# CY8C5667AXI_LP040 register map
File version: 0.1
CY8C56LP
Registers are 8-bit, read-write, no defined reset value unless marked. A register's access mark holds for its fields unless they carry their own. Offsets are from the block's base; lines under a group give offsets from that group; [hi:lo] are bit positions; {n}, {i} and the like mark numbered series; 'fields as' and 'values as' point back to an identical list; <NAME> marks a mode.

## Memory map
0x00000000 ResistiveTouch_1_ADC
0x00000000 UART_1 — UART
0x00000000 DESULFATE_PWMGEN
0x00000000 BACKLIGHT_PWMGEN
0x00000000 SPIS_1
0x00000000 I2C_1
0x00000000 RTC_1 — RTC
0x40006463 TMP05_1_TMP05_STS
0x4000646A FAN_STATUS_REG
0x40006479 PWM_ENABLE_REG
0x40006578 SENSOR_SELECT

## PWM_ENABLE_REG
Base 0x40006479
0x00 PWM_ENABLE_REG_CONTROL_REG

## SENSOR_SELECT
Base 0x40006578
Registers as PWM_ENABLE_REG (with PWM_ENABLE_REG read as SENSOR_SELECT).

## UART_1 — UART
Base 0x00000000
0x40006425 RX_UART_1_RX_ADDRESS1 — RX Address1 Register
0x40006435 RX_UART_1_RX_ADDRESS2 — RX Address2 Register
0x40006445 RX_UART_1_RX_DATA — RX Data Register
0x40006447 TX_UART_1_TX_DATA — TX Data Register
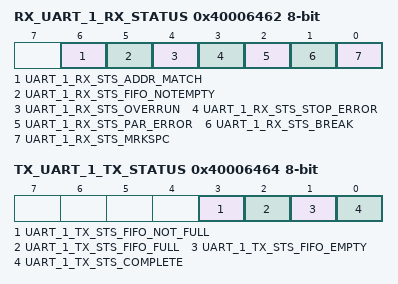
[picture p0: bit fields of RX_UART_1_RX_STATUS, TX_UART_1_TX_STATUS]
0x40006462 RX_UART_1_RX_STATUS — RX status register
  [6] UART_1_RX_STS_ADDR_MATCH ro, [5] UART_1_RX_STS_FIFO_NOTEMPTY ro, [4] UART_1_RX_STS_OVERRUN ro, [3] UART_1_RX_STS_STOP_ERROR ro, [2] UART_1_RX_STS_PAR_ERROR ro, [1] UART_1_RX_STS_BREAK ro, [0] UART_1_RX_STS_MRKSPC ro
0x40006464 TX_UART_1_TX_STATUS — TX status register
  [3] UART_1_TX_STS_FIFO_NOT_FULL ro, [2] UART_1_TX_STS_FIFO_FULL ro, [1] UART_1_TX_STS_FIFO_EMPTY ro, [0] UART_1_TX_STS_COMPLETE ro

## FAN_STATUS_REG
Base 0x4000646A
0x00 FAN_STATUS_REG_STATUS_REG
0x20 FAN_STATUS_REG_MASK_REG
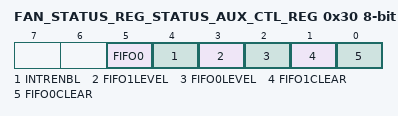
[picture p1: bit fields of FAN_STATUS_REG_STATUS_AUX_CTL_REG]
0x30 FAN_STATUS_REG_STATUS_AUX_CTL_REG
  [5] FIFO0 — FIFO0 clear
    1=ENABLED (Enable counter); 0=DISABLED (Disable counter)
  [4] INTRENBL — Enables or disables the Interrupt
    1=ENABLED (Interrupt enabled); 0=DISABLED (Interrupt disabled)
  [3] FIFO1LEVEL — FIFO level
    1=ENABLED (FIFO LVL: input mode: FIFO at least 1/2 empty; output mode: FIFO at least 1/2 full); 0=DISABLED (FIFO LVL: input mode: FIFO not full; output mode: FIFO not empty)
  [2] FIFO0LEVEL — FIFO level
    values as FIFO1LEVEL
  [1] FIFO1CLEAR — FIFO clear
    1=ENABLED (Clear FIFO state); 0=DISABLED (Normal FIFO operation)
  [0] FIFO0CLEAR — FIFO clear
    values as FIFO1CLEAR

## TMP05_1_TMP05_STS
Base 0x40006463
Registers as FAN_STATUS_REG (with FAN_STATUS_REG read as TMP05_1_TMP05_STS).

## DESULFATE_PWMGEN
Base 0x00000000
0x40006526 DESULFATE_PWMGEN_COMPARE_Reg_ — UDB.D0 - Assigned Compare Value
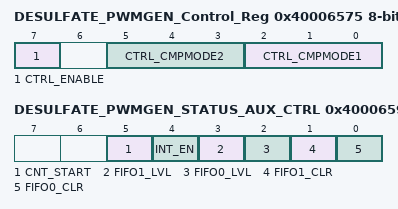
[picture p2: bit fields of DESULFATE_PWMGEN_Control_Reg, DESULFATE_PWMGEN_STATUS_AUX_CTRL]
0x40006575 DESULFATE_PWMGEN_Control_Reg — UDB Control Register - Assigned Control Register Value
  [7] CTRL_ENABLE — Enable the PWM
  [5:3] CTRL_CMPMODE2 — Compare mode 2
  [2:0] CTRL_CMPMODE1 — Compare mode 1
0x40006596 DESULFATE_PWMGEN_STATUS_AUX_CTRL — UDB Auxilliary Control Register
  [5] CNT_START — FIFO0 clear
    0=E_CNT_START0 (Disable counter); 1=E_CNT_START1 (Enable counter)
  [4] INT_EN
    0=E_INT_EN0 (Interrupt disabled); 1=E_INT_EN1 (Interrupt enabled)
  [3] FIFO1_LVL — FIFO level
    0=E_FIFO_LVL_0 (FIFO LVL: input mode: FIFO not full; output mode: FIFO not empty); 1=E_FIFO_LVL_1 (FIFO LVL: input mode: FIFO at least 1/2 empty; output mode: FIFO at least 1/2 full)
  [2] FIFO0_LVL — FIFO level
    values as FIFO1_LVL
  [1] FIFO1_CLR — FIFO1 clear
    0=E_FIFO_CLR_0 (Normal FIFO operation); 1=E_FIFO_CLR_1 (Clear FIFO state)
  [0] FIFO0_CLR — FIFO0 clear
    values as FIFO1_CLR

## BACKLIGHT_PWMGEN
Base 0x00000000
0x400043A3 BACKLIGHT_PWMGEN_GLOBAL_ENABLE — PM.ACT.CFG
  [3:0] en_timer — Enable timer/counters.
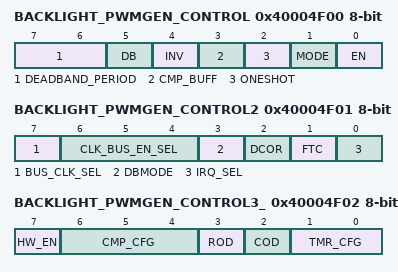
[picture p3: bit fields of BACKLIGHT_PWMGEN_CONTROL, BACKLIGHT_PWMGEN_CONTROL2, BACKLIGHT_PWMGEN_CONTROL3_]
0x40004F00 BACKLIGHT_PWMGEN_CONTROL — TMRx.CFG0
  [7:6] DEADBAND_PERIOD
  [5] DB — Deadband mode--Deadband phases phi1 and phi2 are outputted on CMP and TC output pins respectively.
    0=Timer (CMP and TC are output.); 1=Deadband (PHI1 (instead of CMP) and PHI2 (instead of TC) are output.)
  [4] INV — Invert sense of TIMEREN signal
  [3] CMP_BUFF — Buffer compare register. Compare register updates only on timer terminal count.
  [2] ONESHOT — Timer stops upon reaching stop condition defined by TMR_CFG bits. Can be restarted by asserting TIMER RESET or disabling and re-enabling block.
  [1] MODE — Mode. (0 = Timer; 1 = Comparator)
    0=Timer mode. CNT/CMP register holds timer count value.; 1=Comparator mode. CNT/CMP register holds comparator threshold value.
  [0] EN — Enables timer/comparator.
0x40004F01 BACKLIGHT_PWMGEN_CONTROL2 — TMRx.CFG1
  [7] BUS_CLK_SEL — Bus Clock selection.
  [6:4] CLK_BUS_EN_SEL — Digital Global Clock selection.
  [3] DBMODE — Deadband mode (asynchronous/synchronous). CMP output pin is also affected when not in deadband mode (CFG0.DEADBAND).
  [2] DCOR — Disable Clear on Read (DCOR) of Status Register SR0.
  [1] FTC — First Terminal Count (FTC). Setting this bit forces a single pulse on the TC pin when first enabled.
    0=Disable_FTC (Disable the single cycle pulse, which signifies the timer is starting.); 1=Enable_FTC (Enable the single cycle pulse, which signifies the timer is starting.)
  [0] IRQ_SEL — Irq selection. (0 = raw interrupts; 1 = status register interrupts)
0x40004F02 BACKLIGHT_PWMGEN_CONTROL3_ — TMRx.CFG2
  [7] HW_EN — When set Timer Enable controls counting.
  [6:4] CMP_CFG — Comparator configurations
    0=Equal (Compare Equal); 1=Less_than (Compare Less Than); 2=Less_than_or_equal (Compare Less Than or Equal .); 3=Greater (Compare Greater Than .); 4=Greater_than_or_equal (Compare Greater Than or Equal)
  [3] ROD — Reset On Disable (ROD). Resets internal state of output logic
  [2] COD — Clear On Disable (COD). Clears or gates outputs to zero.
  [1:0] TMR_CFG — Timer configuration (MODE = 0): 000 = Continuous; 001 = Pulsewidth; 010 = Period; 011 = Stop on IRQ
    0=Continuous (Timer runs while EN bit of CFG0 register is set to '1'.); 1=Pulsewidth (Timer runs from positive to negative edge of TIMEREN.); 2=Period (Timer runs from positive to positive edge of TIMEREN.); 3=Irq (Timer runs until IRQ.)
0x40004F04 BACKLIGHT_PWMGEN_PERIOD — TMRx.PER0 - Assigned Period
0x40004F06 BACKLIGHT_PWMGEN_COMPARE — TMRx.CNT_CMP0 - Assigned Compare Value
